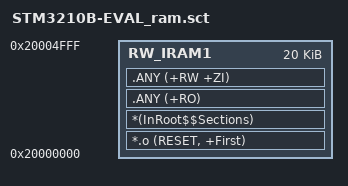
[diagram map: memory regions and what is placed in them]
; *************************************************************
; *** Scatter-Loading Description File generated by uVision ***
; *************************************************************

LR_IROM1 0x20000000 0x00005000  {    ; load region size_region 
  RW_IRAM1 0x20000000 0x00005000  {  ; RW data
   *.o (RESET, +First)
   *(InRoot$$Sections)
   .ANY (+RO)
   .ANY (+RW +ZI)
  }
}

